# MCU_NAVSS0_UDMASS_UDMAP0_TCHAN register map
Vendor: Texas Instruments
Peripheral module from a debugger description file (folder J7ES).
Registers are 32-bit, read-write, reset 0x0 unless marked. A register's access mark holds for its fields unless they carry their own. Offsets are as the file gives them; lines under a group give offsets from that group; [hi:lo] are bit positions; {n}, {i} and the like mark numbered series; 'fields as' and 'values as' point back to an identical list; <NAME> marks a mode.

## MCU_NAVSS0_UDMASS_UDMAP0_TCHAN
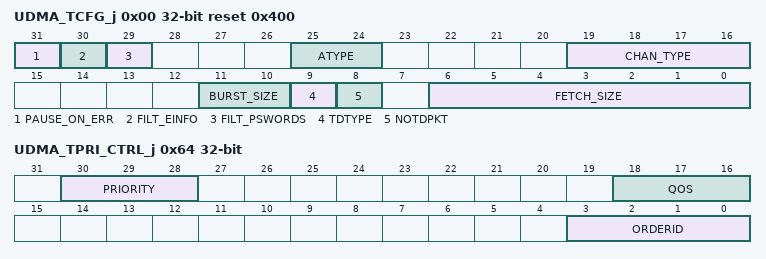
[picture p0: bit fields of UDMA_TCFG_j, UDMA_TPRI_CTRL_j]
0x00 UDMA_TCFG_j reset 0x400 — The Tx Channel Configuration Register is used to initialize static mode settings for the Tx DMA channel. This register may only be written when the channel is disabled (tx_enable in realtime control reg is 0). Offset = 0h + (j * 100h); where j = 0h to 12B for NAVSS0_UDMASS_UDMAP0_CFG_TCHAN j = 0h to 2Fh for MCU_NAVSS0_UDMASS_UDMAP0_TCHAN
  [31] PAUSE_ON_ERR — Pause On Error: this field controls what the channel will do if an error or exception occurs during a data transfer. This field is encoded as follows: 0 = Channel will drop current work and move on 1 = Channel will pause and wait for SW to investigate and un-pause the channel.
  [30] FILT_EINFO — This field controls whether or not the DMA controller will pass the extended packet information fields (if present) from the descriptor to the back end application. This field is encoded as follows: 0=DMA controller will pass extended packet info words if they are present in the descriptor 1=DMA controller will filter extended packet info words.
  [29] FILT_PSWORDS — This field controls whether or not the DMA controller will pass the protocol specific words (if present) from the descriptor to the back end application. This field is encoded as follows: 0=DMA controller will pass PS words if present in descriptor 1=DMA controller will filter PS words.
  [25:24] ATYPE — This field controls how pointers will be interpreted for non Ring Accelerator accesses on this channel. The values are encoded as follows: 0 = Pointers are physical addresses 1 = Pointers are intermediate addresses which require intermediate to physical transaction before they can be decoded 2 = Pointers are virtual addresses which require virtual to physical translation before they can be decoded. All transactions from this channel which are not destined to the Ring Accelerator will have the mem*_catype attribute set equal to the value given in this register field. Accesses to the RA will always use physical addresses.
  [19:16] CHAN_TYPE — Tx Channel Type: this field controls and / or indicates the functional channel type for this channel and the work passing mechanism that the channel uses for communicating with the Host. Available channel types are as follows: 0 = RESERVED 1 = RESERVED 2 = Channel performs packet oriented data transfers using pass by reference rings. Channels configured in this mode can only use Host and Monolithic descriptors and the pointers to those descriptors are passed from/to SW using rings in the Ring Accelerator. 3- 9 = RESERVED 10 = Channel performs Third Party DMA transfers using pass by reference rings. Channels configured in this mode can only use TR descriptors and the pointers to those descriptors are passed from/to SW using rings in the Ring Accelerator. 11 = Channel performs Third Party DMA transfers using pass by value rings. Channels configured in this mode will directly pass individual Transfer Request/Transfer Response messages from/to SW using rings in the Ring Accelerator. 12 = Channel performs Third Party Block Copy DMA transfers using pass by reference rings. Channels configured in this mode are linked to the same index Rx channel to form a bonded read/write channel 13 = Channel performs Third Party Block Copy DMA transfers using pass by value rings. Channels configured in this mode are linked to the same index Rx channel to form a bonded read/write channel 14 = Channel performs Third Party DMA transfers using TRs provided via PSI-L (not supported in UDMA-P). 15 = Channel performs Third Party DMA transfers using TRs provided via QDMA channel (not supported in UDMA-P)
  [11:10] BURST_SIZE — Specifies the nominal burst size and alignment for data transfers on this channel.
  [9] TDTYPE — Specifies whether or not the channel should immediately return a teardown completion response to the default completion queue or wait until a status message is returned from the remote PSI-L paired peripheral.
  [8] NOTDPKT — Specifies whether or not the channel should suppress sending the single data phase teardown packet when teardown is complete. 0 = TD packet is sent 1 = Suppress sending TD packet
  [6:0] FETCH_SIZE — Specifies the # of 32-bit descriptor words to fetch. This must be set to the maximum word count that can pass through the channel for any allowed descriptor type.
0x04 UDMA_TCREDIT_j — The Transfer Request Credit Register indicates how many TR sized buffer slots exist in the associated UTC channel to which this channel is associated. This register only exists for external UTC channels. This field should not be changed while the channel is in operation. Offset = 4h + (j * 100h); where j = 0h to 12B for NAVSS0_UDMASS_UDMAP0_CFG_TCHAN j = 0h to 2Fh for MCU_NAVSS0_UDMASS_UDMAP0_TCHAN
  [2:0] COUNT — Transfer Request Credit Count: this field specifies how many credits for complete TRs are available. This field should be initialized before the channel is enabled and will then increment/decrement as TRs are submitted and responses are received.
0x14 UDMA_TCQ_j — The Tx Channel Completion Queue Register is used to specify which queue the Transfer Responses will be returned to when operating in the pass by value channel mode. This register may only be written when the channel is disabled (tx_enable in realtime control reg is 0). Offset = 14h + (j * 100h); where j = 0h to 12B for NAVSS0_UDMASS_UDMAP0_CFG_TCHAN j = 0h to 2Fh for MCU_NAVSS0_UDMASS_UDMAP0_TCHAN
  [15:0] TXCQ_QNUM — Specifies the queue number to return pass by value Transfer Responses and teardown completion teardown messages to.
0x20 UDMA_TOES_j reset 0xFFFF — The Output Event Steering Registers are used to specify a global event number to generate anytime the required event generation criteria specified in a TR are met. A single event with the event number set equal to the value in the corresponding register will be generated. This register is provided in order to allow security SW to lock down which events in the global space any given channel/ thread is allowed to generate. Offset = 20h + (j * 100h); where j = 0h to 12B for NAVSS0_UDMASS_UDMAP0_CFG_TCHAN j = 0h to 2Fh for MCU_NAVSS0_UDMASS_UDMAP0_TCHAN
  [15:0] EVT_NUM — This is the global event number to be generated
0x60 UDMA_TEOES_j reset 0xFFFF — The Error Output Event Steering Registers are used to specify a global event number to generate anytime an error is encountered on the channel. A single event with the event number set equal to the value in the corresponding register will be generated. This register is provided in order to allow security SW to lock down which events in the global space any given channel/ thread is allowed to generate. Offset = 60h + (j * 100h); where j = 0h to 12B for NAVSS0_UDMASS_UDMAP0_CFG_TCHAN j = 0h to 2Fh for MCU_NAVSS0_UDMASS_UDMAP0_TCHAN
  [15:0] EVT_NUM — This is the global event number to be generated
0x64 UDMA_TPRI_CTRL_j — The priority control register is used to control the priority of the transactions which the DMA generates on it's master interface. Offset = 64h + (j * 100h); where j = 0h to 12B for NAVSS0_UDMASS_UDMAP0_CFG_TCHAN j = 0h to 2Fh for MCU_NAVSS0_UDMASS_UDMAP0_TCHAN
  [30:28] PRIORITY — Tx Priority: This field contains the 3-bit value which will be output on the mem*_cpriority and mem_cepriority outputs during all transactions for this channel.
  [18:16] QOS — Tx Quality of Service Level: This field contains the 3-bit value which will be output on the mem*_cqos output during all transactions for this channel.
  [3:0] ORDERID — Tx Order ID: This field contains the 4-bit value which will be output on the mem*_corderid output during all transactions for this channel.
0x68 UDMA_THREAD_j — The thread ID mapping register is used to pair the Tx DMA channel to a specific destination thread. All traffic generated from this channel will be sent with a thread_id on the PSI-L interface with the value from this register. Offset = 68h + (j * 100h); where j = 0h to 12B for NAVSS0_UDMASS_UDMAP0_CFG_TCHAN j = 0h to 2Fh for MCU_NAVSS0_UDMASS_UDMAP0_TCHAN
  [15:0] ID — Thread ID: This field contains the 16-bit value which will be output on the strm_o_thread_id output during all transactions for this channel.
0x70 UDMA_TFIFO_DEPTH_j reset 0x1000 — The fifo depth register is used to specify how many FIFO data phases deep the Tx per channel FIFO will be for the channel. While the maximum depth of the Tx FIFO is set at design time, the FIFO depth can be artificially reduced in order to control the maximum latency which can be introduced due to buffering effects. Offset = 70h + (j * 100h); where j = 0h to 12B for NAVSS0_UDMASS_UDMAP0_CFG_TCHAN j = 0h to 2Fh for MCU_NAVSS0_UDMASS_UDMAP0_TCHAN
  [12:0] FDEPTH — FIFO Depth: This field contains the number of Tx FIFO bytes which will be allowed to be stored for the channel.
0x80 UDMA_TST_SCHED_j — The Tx Channel N Static Scheduler Configuration Register contains static configuration information which affects the conditions under which each channel will be given an opportunity to use the Tx DMA unit(s). The fields in this register are as follows: Offset = 80h + (j * 100h); where j = 0h to 12B for NAVSS0_UDMASS_UDMAP0_CFG_TCHAN j = 0h to 2Fh for MCU_NAVSS0_UDMASS_UDMAP0_TCHAN
  [1:0] PRIORITY — Tx Scheduling Priority: These bits select which scheduling bin the channel will be placed in for bandwidth allocation of the Tx DMA units. This field is encoded as follows: 0 = High priority 1 = Medium - high priority 2 = Medium - low priority 3 = Low priority Arbitration between bins is performed in a strict priority fashion. High priority channels will always be serviced first. If no high priority channels are requesting then all medium-high priority channels will be serviced next. If no high priority or medium-high priority channels are requesting then all medium-low priority channels will be serviced next. When no other channels are requesting, the low priority channels will be serviced. All channels within a given bin are serviced in a round robin order. Only channels which are enabled and which have sufficient free space in their Per Channel FIFO will be included in the round robin arbitration.
